# DECODER0_ENTROPY_DMAC register map
Vendor: Texas Instruments
Peripheral module from a debugger description file (folder J7ES).
Registers are 32-bit, read-write, reset 0x0 unless marked. A register's access mark holds for its fields unless they carry their own. Offsets are as the file gives them; lines under a group give offsets from that group; [hi:lo] are bit positions; {n}, {i} and the like mark numbered series; 'fields as' and 'values as' point back to an identical list; <NAME> marks a mode.

## DECODER0_ENTROPY_DMAC
{0x0+0x20*i} DECODER0_DMAC_SETUP_{i:02} (i=0..5)
  [31:0] START_ADDRESS — If LIST_EN = '1' then
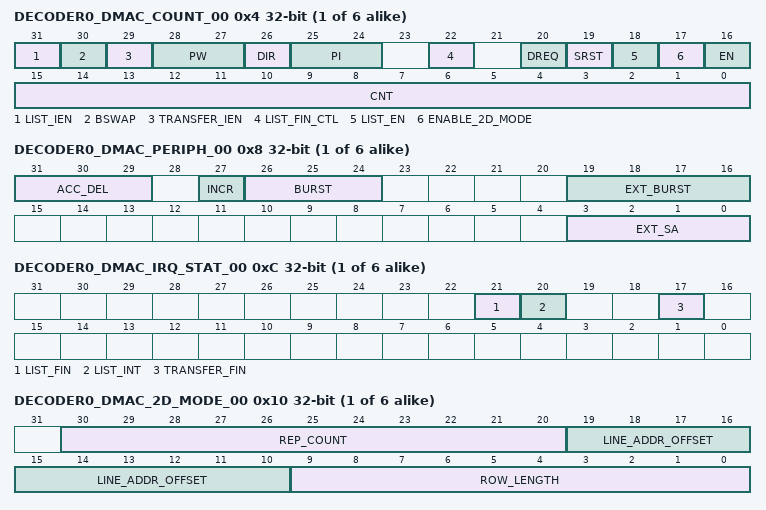
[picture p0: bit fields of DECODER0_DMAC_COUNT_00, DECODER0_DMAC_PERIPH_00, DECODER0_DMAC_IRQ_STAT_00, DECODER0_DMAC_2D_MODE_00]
{0x4+0x20*i} DECODER0_DMAC_COUNT_{i:02} (i=0..5)
  [31] LIST_IEN
  [30] BSWAP
  [29] TRANSFER_IEN
  [28:27] PW
  [26] DIR
  [25:24] PI — Specifies how much to increment the peripheral address by i [only set when LIST_EN = '0'] 0i0
  [22] LIST_FIN_CTL
  [20] DREQ
  [19] SRST
  [18] LIST_EN
  [17] ENABLE_2D_MODE — 2D DMA transfer mode enable.
  [16] EN
  [15:0] CNT
{0x8+0x20*i} DECODER0_DMAC_PERIPH_{i:02} (i=0..5)
  [31:29] ACC_DEL
  [27] INCR
  [26:24] BURST
  [19:16] EXT_BURST — Additional bits for BURST if a burst size of 8 or larger is required.
  [3:0] EXT_SA — If LIST_EN = '1' then
{0xC+0x20*i} DECODER0_DMAC_IRQ_STAT_{i:02} (i=0..5)
  [21] LIST_FIN
  [20] LIST_INT — List element status for current linked-list state.
  [17] TRANSFER_FIN
{0x10+0x20*i} DECODER0_DMAC_2D_MODE_{i:02} (i=0..5)
  [30:20] REP_COUNT, [19:10] LINE_ADDR_OFFSET, [9:0] ROW_LENGTH
{0x14+0x20*i} DECODER0_DMAC_PERIPHERAL_ADDR_{i:02} (i=0..5)
  [22:0] ADDR — Specifies the address of the peripheral register to be accessed in this DMA channel.
{0x18+0x20*i} DECODER0_DMAC_PER_HOLD_{i:02} reset 0x7 (i=0..5)
  [4:0] PER_HOLD — Specifies the holdover period to use for the channel.
0xC0 DECODER0_DMAC_SOFT_RESET
  [0] SOFT_RESET
